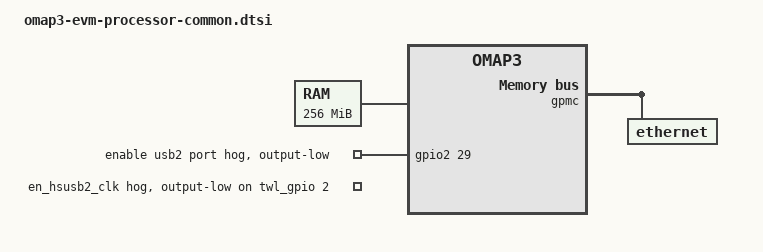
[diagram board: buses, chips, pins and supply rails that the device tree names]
/ {
	memory@80000000 {
		device_type = "memory";
		reg = <0x80000000 0x10000000>;  
	};
	wl12xx_vmmc: wl12xx_vmmc {
		pinctrl-names = "default";
		pinctrl-0 = <&wl12xx_gpio>;
	};
};
&dss {
	vdds_dsi-supply = <&vpll2>;
	vdda_video-supply = <&lcd_3v3>;
	pinctrl-names = "default";
	pinctrl-0 = <
		&dss_dpi_pins1
		&dss_dpi_pins2
	>;
};
&hsusb2_phy {
	pinctrl-names = "default";
	pinctrl-0 = <&ehci_phy_pins>;
};
&omap3_pmx_core {
	pinctrl-names = "default";
	pinctrl-0 = <&on_board_gpio_61 &hsusb2_pins>;
	dss_dpi_pins1: dss-dpi2-pins {
		pinctrl-single,pins = <
			OMAP3_CORE1_IOPAD(0x20d4, PIN_OUTPUT | MUX_MODE0)    
			OMAP3_CORE1_IOPAD(0x20d6, PIN_OUTPUT | MUX_MODE0)    
			OMAP3_CORE1_IOPAD(0x20d8, PIN_OUTPUT | MUX_MODE0)    
			OMAP3_CORE1_IOPAD(0x20da, PIN_OUTPUT | MUX_MODE0)    
			OMAP3_CORE1_IOPAD(0x20e8, PIN_OUTPUT | MUX_MODE0)    
			OMAP3_CORE1_IOPAD(0x20ea, PIN_OUTPUT | MUX_MODE0)    
			OMAP3_CORE1_IOPAD(0x20ec, PIN_OUTPUT | MUX_MODE0)    
			OMAP3_CORE1_IOPAD(0x20ee, PIN_OUTPUT | MUX_MODE0)    
			OMAP3_CORE1_IOPAD(0x20f0, PIN_OUTPUT | MUX_MODE0)    
			OMAP3_CORE1_IOPAD(0x20f2, PIN_OUTPUT | MUX_MODE0)    
			OMAP3_CORE1_IOPAD(0x20f4, PIN_OUTPUT | MUX_MODE0)    
			OMAP3_CORE1_IOPAD(0x20f6, PIN_OUTPUT | MUX_MODE0)    
			OMAP3_CORE1_IOPAD(0x20f8, PIN_OUTPUT | MUX_MODE0)    
			OMAP3_CORE1_IOPAD(0x20fa, PIN_OUTPUT | MUX_MODE0)    
			OMAP3_CORE1_IOPAD(0x20fc, PIN_OUTPUT | MUX_MODE0)    
			OMAP3_CORE1_IOPAD(0x20fe, PIN_OUTPUT | MUX_MODE0)    
			OMAP3_CORE1_IOPAD(0x2100, PIN_OUTPUT | MUX_MODE3)    
			OMAP3_CORE1_IOPAD(0x2102, PIN_OUTPUT | MUX_MODE3)    
			OMAP3_CORE1_IOPAD(0x2104, PIN_OUTPUT | MUX_MODE3)    
			OMAP3_CORE1_IOPAD(0x2106, PIN_OUTPUT | MUX_MODE3)    
			OMAP3_CORE1_IOPAD(0x2108, PIN_OUTPUT | MUX_MODE3)    
			OMAP3_CORE1_IOPAD(0x210a, PIN_OUTPUT | MUX_MODE3)    
		>;
	};
	mmc1_pins: mmc1-pins {
		pinctrl-single,pins = <
			OMAP3_CORE1_IOPAD(0x2144, PIN_OUTPUT_PULLUP | MUX_MODE0)	 
			OMAP3_CORE1_IOPAD(0x2146, PIN_INPUT_PULLUP | MUX_MODE0)		 
			OMAP3_CORE1_IOPAD(0x2148, PIN_INPUT_PULLUP | MUX_MODE0) 	 
			OMAP3_CORE1_IOPAD(0x214a, PIN_INPUT_PULLUP | MUX_MODE0) 	 
			OMAP3_CORE1_IOPAD(0x214c, PIN_INPUT_PULLUP | MUX_MODE0) 	 
			OMAP3_CORE1_IOPAD(0x214e, PIN_INPUT_PULLUP | MUX_MODE0) 	 
			OMAP3_CORE1_IOPAD(0x2150, PIN_INPUT_PULLUP | MUX_MODE0) 	 
			OMAP3_CORE1_IOPAD(0x2152, PIN_INPUT_PULLUP | MUX_MODE0) 	 
			OMAP3_CORE1_IOPAD(0x2154, PIN_INPUT_PULLUP | MUX_MODE0) 	 
			OMAP3_CORE1_IOPAD(0x2156, PIN_INPUT_PULLUP | MUX_MODE0) 	 
		>;
	};
	mmc2_pins: mmc2-pins {
		pinctrl-single,pins = <
			OMAP3_CORE1_IOPAD(0x2158, PIN_INPUT_PULLUP | MUX_MODE0)	 
			OMAP3_CORE1_IOPAD(0x215a, PIN_INPUT_PULLUP | MUX_MODE0)	 
			OMAP3_CORE1_IOPAD(0x215c, PIN_INPUT_PULLUP | MUX_MODE0)	 
			OMAP3_CORE1_IOPAD(0x215e, PIN_INPUT_PULLUP | MUX_MODE0)  
			OMAP3_CORE1_IOPAD(0x2160, PIN_INPUT_PULLUP | MUX_MODE0)	 
			OMAP3_CORE1_IOPAD(0x2162, PIN_INPUT_PULLUP | MUX_MODE0)	 
			OMAP3_CORE1_IOPAD(0x2164, PIN_OUTPUT | MUX_MODE1)	 
			OMAP3_CORE1_IOPAD(0x2166, PIN_OUTPUT | MUX_MODE1)	 
			OMAP3_CORE1_IOPAD(0x2168, PIN_OUTPUT | MUX_MODE1)	 
			OMAP3_CORE1_IOPAD(0x216a, PIN_INPUT | MUX_MODE1)	 
		>;
	};
	uart3_pins: uart3-pins {
		pinctrl-single,pins = <
			OMAP3_CORE1_IOPAD(0x219e, WAKEUP_EN | PIN_INPUT | MUX_MODE0)  
			OMAP3_CORE1_IOPAD(0x21a0, PIN_OUTPUT | MUX_MODE0)		 
		>;
	};
	on_board_gpio_61: ehci-port-select-pins {
		pinctrl-single,pins = <
		OMAP3_CORE1_IOPAD(0x20c8, PIN_OUTPUT | MUX_MODE4)
		>;
	};
	hsusb2_pins: hsusb2-pins {
		pinctrl-single,pins = <
		OMAP3_CORE1_IOPAD(0x21d4, PIN_INPUT_PULLDOWN | MUX_MODE3)
		OMAP3_CORE1_IOPAD(0x21d6, PIN_INPUT_PULLDOWN | MUX_MODE3)
		OMAP3_CORE1_IOPAD(0x21d8, PIN_INPUT_PULLDOWN | MUX_MODE3)
		OMAP3_CORE1_IOPAD(0x21da, PIN_INPUT_PULLDOWN | MUX_MODE3)
		OMAP3_CORE1_IOPAD(0x21dc, PIN_INPUT_PULLDOWN | MUX_MODE3)
		OMAP3_CORE1_IOPAD(0x21de, PIN_INPUT_PULLDOWN | MUX_MODE3)
		>;
	};
	wl12xx_gpio: wl12xx-gpio-pins {
		pinctrl-single,pins = <
			OMAP3_CORE1_IOPAD(0x2180, PIN_INPUT_PULLUP | MUX_MODE7)		 
			OMAP3_CORE1_IOPAD(0x217e, PIN_INPUT | MUX_MODE4)		 
		>;
	};
	smsc911x_pins: smsc911x-pins {
		pinctrl-single,pins = <
			OMAP3_CORE1_IOPAD(0x21d2, PIN_INPUT | MUX_MODE4)		 
		>;
	};
};
&omap3_pmx_wkup {
	dss_dpi_pins2: dss-dpi1-pins {
		pinctrl-single,pins = <
			OMAP3_WKUP_IOPAD(0x2a0a, PIN_OUTPUT | MUX_MODE3)    
			OMAP3_WKUP_IOPAD(0x2a0c, PIN_OUTPUT | MUX_MODE3)    
			OMAP3_WKUP_IOPAD(0x2a10, PIN_OUTPUT | MUX_MODE3)    
			OMAP3_WKUP_IOPAD(0x2a12, PIN_OUTPUT | MUX_MODE3)    
			OMAP3_WKUP_IOPAD(0x2a14, PIN_OUTPUT | MUX_MODE3)    
			OMAP3_WKUP_IOPAD(0x2a16, PIN_OUTPUT | MUX_MODE3)    
		>;
	};
};
&mmc1 {
	pinctrl-names = "default";
	pinctrl-0 = <&mmc1_pins>;
};
&mmc2 {
	pinctrl-names = "default";
	pinctrl-0 = <&mmc2_pins>;
};
&mmc3 {
	status = "disabled";
};
&uart1 {
	interrupts-extended = <&intc 72 &omap3_pmx_core OMAP3_UART1_RX>;
};
&uart2 {
	interrupts-extended = <&intc 73 &omap3_pmx_core OMAP3_UART2_RX>;
};
&uart3 {
	interrupts-extended = <&intc 74 &omap3_pmx_core OMAP3_UART3_RX>;
	pinctrl-names = "default";
	pinctrl-0 = <&uart3_pins>;
};
&gpio2 {
	en-usb2-port-hog {
		gpio-hog;
		gpios = <29 GPIO_ACTIVE_HIGH>;	 
		output-low;
		line-name = "enable usb2 port";
	};
};
&twl_gpio {
	en_on_board_gpio_61 {
		gpio-hog;
		gpios = <2 GPIO_ACTIVE_HIGH>;
		output-low;
		line-name = "en_hsusb2_clk";
	};
};
&gpmc {
	ranges = <0 0 0x30000000 0x1000000>,	 
		 <5 0 0x2c000000 0x01000000>;	 
	ethernet@gpmc {
		pinctrl-names = "default";
		pinctrl-0 = <&smsc911x_pins>;
	};
};
